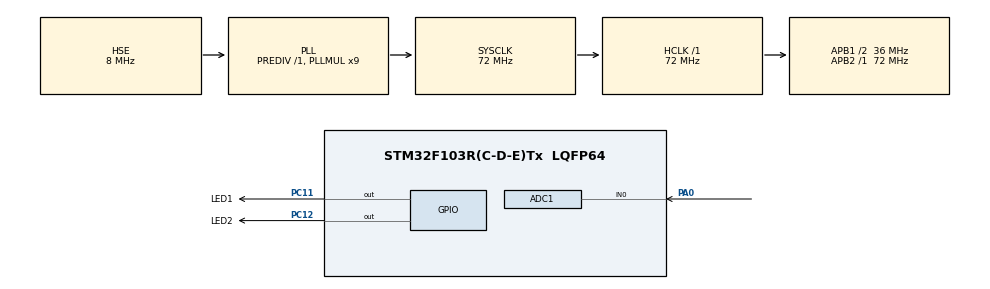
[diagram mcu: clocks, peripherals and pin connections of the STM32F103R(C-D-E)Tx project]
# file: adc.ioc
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ADC1.Channel-0\#ChannelRegularConversion=ADC_CHANNEL_0
ADC1.ContinuousConvMode=ENABLE
ADC1.DataAlign=ADC_DATAALIGN_RIGHT
ADC1.DiscontinuousConvMode=DISABLE
ADC1.EnableAnalogWatchDog=false
ADC1.EnableRegularConversion=ENABLE
ADC1.ExternalTrigConv=ADC_SOFTWARE_START
ADC1.InjNumberOfConversion=0
ADC1.NbrOfConversion=1
ADC1.NbrOfConversionFlag=1
ADC1.Rank-0\#ChannelRegularConversion=1
ADC1.SamplingTime-0\#ChannelRegularConversion=ADC_SAMPLETIME_1CYCLE_5
ADC1.ScanConvMode=ADC_SCAN_DISABLE
ADC1.master=1
Dma.ADC1.0.Direction=DMA_PERIPH_TO_MEMORY
Dma.ADC1.0.Instance=DMA1_Channel1
Dma.ADC1.0.MemDataAlignment=DMA_MDATAALIGN_HALFWORD
Dma.ADC1.0.MemInc=DMA_MINC_ENABLE
Dma.ADC1.0.Mode=DMA_CIRCULAR
Dma.ADC1.0.PeriphDataAlignment=DMA_PDATAALIGN_HALFWORD
Dma.ADC1.0.PeriphInc=DMA_PINC_DISABLE
Dma.ADC1.0.Priority=DMA_PRIORITY_LOW
Dma.Request0=ADC1
Mcu.Family=STM32F1
Mcu.Name=STM32F103R(C-D-E)Tx
Mcu.Package=LQFP64
NVIC.ADC1_2_IRQn=true\:1\:0\:true\:false\:true\:true
NVIC.DMA1_Channel1_IRQn=true\:0\:0\:false\:false\:true\:false
NVIC.PriorityGroup=NVIC_PRIORITYGROUP_4
PA0-WKUP.Signal=ADCx_IN0
PA13.Mode=Serial_Wire
PA13.Signal=SYS_JTMS-SWDIO
PA14.Mode=Serial_Wire
PA14.Signal=SYS_JTCK-SWCLK
PC11.GPIO_Label=LED1
PC11.Signal=GPIO_Output
PC12.GPIO_Label=LED2
PC12.Signal=GPIO_Output
PD0-OSC_IN.Mode=HSE-External-Oscillator
PD0-OSC_IN.Signal=RCC_OSC_IN
PD1-OSC_OUT.Mode=HSE-External-Oscillator
PD1-OSC_OUT.Signal=RCC_OSC_OUT
ProjectManager.HeapSize=0x200
ProjectManager.StackSize=0x400
ProjectManager.TargetToolchain=MDK-ARM V5
RCC.ADCPresc=RCC_ADCPCLK2_DIV6
RCC.AHBFreq_Value=72000000
RCC.APB1CLKDivider=RCC_HCLK_DIV2
RCC.APB1Freq_Value=36000000
RCC.APB1TimFreq_Value=72000000
RCC.APB2Freq_Value=72000000
RCC.APB2TimFreq_Value=72000000
RCC.HCLKFreq_Value=72000000
RCC.PLLMUL=RCC_PLL_MUL9
RCC.PLLSourceVirtual=RCC_PLLSOURCE_HSE
RCC.SYSCLKFreq_VALUE=72000000
RCC.SYSCLKSource=RCC_SYSCLKSOURCE_PLLCLK
RCC.USBFreq_Value=72000000
SH.ADCx_IN0.0=ADC1_IN0,IN0
board=adc

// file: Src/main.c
/**
  ******************************************************************************
  * File Name          : main.c
  * Description        : Main program body
  ******************************************************************************
  ** This notice applies to any and all portions of this file
  * that are not between comment pairs USER CODE BEGIN and
  * USER CODE END. Other portions of this file, whether
  * inserted by the user or by software development tools
  * are owned by their respective copyright owners.
  *
  * COPYRIGHT(c) 2020 STMicroelectronics
  *
  * Redistribution and use in source and binary forms, with or without modification,
  * are permitted provided that the following conditions are met:
  *   1. Redistributions of source code must retain the above copyright notice,
  *      this list of conditions and the following disclaimer.
  *   2. Redistributions in binary form must reproduce the above copyright notice,
  *      this list of conditions and the following disclaimer in the documentation
  *      and/or other materials provided with the distribution.
  *   3. Neither the name of STMicroelectronics nor the names of its contributors
  *      may be used to endorse or promote products derived from this software
  *      without specific prior written permission.
  *
  * THIS SOFTWARE IS PROVIDED BY THE COPYRIGHT HOLDERS AND CONTRIBUTORS "AS IS"
  * AND ANY EXPRESS OR IMPLIED WARRANTIES, INCLUDING, BUT NOT LIMITED TO, THE
  * IMPLIED WARRANTIES OF MERCHANTABILITY AND FITNESS FOR A PARTICULAR PURPOSE ARE
  * DISCLAIMED. IN NO EVENT SHALL THE COPYRIGHT HOLDER OR CONTRIBUTORS BE LIABLE
  * FOR ANY DIRECT, INDIRECT, INCIDENTAL, SPECIAL, EXEMPLARY, OR CONSEQUENTIAL
  * DAMAGES (INCLUDING, BUT NOT LIMITED TO, PROCUREMENT OF SUBSTITUTE GOODS OR
  * SERVICES; LOSS OF USE, DATA, OR PROFITS; OR BUSINESS INTERRUPTION) HOWEVER
  * CAUSED AND ON ANY THEORY OF LIABILITY, WHETHER IN CONTRACT, STRICT LIABILITY,
  * OR TORT (INCLUDING NEGLIGENCE OR OTHERWISE) ARISING IN ANY WAY OUT OF THE USE
  * OF THIS SOFTWARE, EVEN IF ADVISED OF THE POSSIBILITY OF SUCH DAMAGE.
  *
  ******************************************************************************
  */

#include "main.h"
#include "stm32f1xx_hal.h"

ADC_HandleTypeDef hadc1;
DMA_HandleTypeDef hdma_adc1;

/* USER CODE BEGIN PV */
/* Private variables ---------------------------------------------------------*/
volatile uint32_t adc ;
/* USER CODE END PV */

void SystemClock_Config(void);
static void MX_GPIO_Init(void);
static void MX_DMA_Init(void);
static void MX_ADC1_Init(void);

/* USER CODE BEGIN PFP */
/* Private function prototypes -----------------------------------------------*/

/* USER CODE END PFP */

/* USER CODE BEGIN 0 */
void HAL_ADC_ConvCpltCallback(ADC_HandleTypeDef* hadc)
{
	//HAL_ADC_Start(&hadc1);
	if(hadc->Instance==hadc1.Instance){
		if(HAL_ADC_GetValue(&hadc1) > 3000){
			HAL_GPIO_WritePin(LED2_GPIO_Port, LED2_Pin,GPIO_PIN_SET);
			HAL_GPIO_WritePin(LED1_GPIO_Port,LED1_Pin,GPIO_PIN_RESET);
			adc = HAL_ADC_GetValue(&hadc1);
		}
		else {
			HAL_GPIO_WritePin(LED2_GPIO_Port,LED2_Pin,0);
			adc= 0;
			HAL_ADC_Stop_IT(&hadc1);

		}
	}
}

/* USER CODE END 0 */

int main(void)
{

  /* MCU Configuration----------------------------------------------------------*/

  /* Reset of all peripherals, Initializes the Flash interface and the Systick. */
  HAL_Init();

  /* Configure the system clock */
  SystemClock_Config();

  /* Initialize all configured peripherals */
  MX_GPIO_Init();
  MX_DMA_Init();
  MX_ADC1_Init();
	HAL_ADC_Start_IT(&hadc1);
	//HAL_ADC_Start(&hadc1);

  /* Infinite loop */
  while (1)
  {
		HAL_GPIO_TogglePin(LED1_GPIO_Port,LED1_Pin);
		HAL_Delay(1000);
		HAL_GPIO_TogglePin(LED2_GPIO_Port,LED2_Pin);
		HAL_Delay(1100);
		HAL_ADC_Start_IT(&hadc1);
  }

}

/** System Clock Configuration
*/

void SystemClock_Config(void)
{

  RCC_OscInitTypeDef RCC_OscInitStruct;
  RCC_ClkInitTypeDef RCC_ClkInitStruct;
  RCC_PeriphCLKInitTypeDef PeriphClkInit;

    /**Initializes the CPU, AHB and APB busses clocks
    */
  RCC_OscInitStruct.OscillatorType = RCC_OSCILLATORTYPE_HSE;
  RCC_OscInitStruct.HSEState = RCC_HSE_ON;
  RCC_OscInitStruct.HSEPredivValue = RCC_HSE_PREDIV_DIV1;
  RCC_OscInitStruct.HSIState = RCC_HSI_ON;
  RCC_OscInitStruct.PLL.PLLState = RCC_PLL_ON;
  RCC_OscInitStruct.PLL.PLLSource = RCC_PLLSOURCE_HSE;
  RCC_OscInitStruct.PLL.PLLMUL = RCC_PLL_MUL9;
  if (HAL_RCC_OscConfig(&RCC_OscInitStruct) != HAL_OK)
  {
    _Error_Handler(__FILE__, __LINE__);
  }

    /**Initializes the CPU, AHB and APB busses clocks
    */
  RCC_ClkInitStruct.ClockType = RCC_CLOCKTYPE_HCLK|RCC_CLOCKTYPE_SYSCLK
                              |RCC_CLOCKTYPE_PCLK1|RCC_CLOCKTYPE_PCLK2;
  RCC_ClkInitStruct.SYSCLKSource = RCC_SYSCLKSOURCE_PLLCLK;
  RCC_ClkInitStruct.AHBCLKDivider = RCC_SYSCLK_DIV1;
  RCC_ClkInitStruct.APB1CLKDivider = RCC_HCLK_DIV2;
  RCC_ClkInitStruct.APB2CLKDivider = RCC_HCLK_DIV1;

  if (HAL_RCC_ClockConfig(&RCC_ClkInitStruct, FLASH_LATENCY_2) != HAL_OK)
  {
    _Error_Handler(__FILE__, __LINE__);
  }

  PeriphClkInit.PeriphClockSelection = RCC_PERIPHCLK_ADC;
  PeriphClkInit.AdcClockSelection = RCC_ADCPCLK2_DIV6;
  if (HAL_RCCEx_PeriphCLKConfig(&PeriphClkInit) != HAL_OK)
  {
    _Error_Handler(__FILE__, __LINE__);
  }

    /**Configure the Systick interrupt time
    */
  HAL_SYSTICK_Config(HAL_RCC_GetHCLKFreq()/1000);

    /**Configure the Systick
    */
  HAL_SYSTICK_CLKSourceConfig(SYSTICK_CLKSOURCE_HCLK);

  /* SysTick_IRQn interrupt configuration */
  HAL_NVIC_SetPriority(SysTick_IRQn, 0, 0);
}

/* ADC1 init function */
static void MX_ADC1_Init(void)
{

  ADC_ChannelConfTypeDef sConfig;

    /**Common config
    */
  hadc1.Instance = ADC1;
  hadc1.Init.ScanConvMode = ADC_SCAN_DISABLE;
  hadc1.Init.ContinuousConvMode = ENABLE;
  hadc1.Init.DiscontinuousConvMode = DISABLE;
  hadc1.Init.ExternalTrigConv = ADC_SOFTWARE_START;
  hadc1.Init.DataAlign = ADC_DATAALIGN_RIGHT;
  hadc1.Init.NbrOfConversion = 1;
  if (HAL_ADC_Init(&hadc1) != HAL_OK)
  {
    _Error_Handler(__FILE__, __LINE__);
  }

    /**Configure Regular Channel
    */
  sConfig.Channel = ADC_CHANNEL_0;
  sConfig.Rank = 1;
  sConfig.SamplingTime = ADC_SAMPLETIME_1CYCLE_5;
  if (HAL_ADC_ConfigChannel(&hadc1, &sConfig) != HAL_OK)
  {
    _Error_Handler(__FILE__, __LINE__);
  }

}

static void MX_DMA_Init(void)
{
  /* DMA controller clock enable */
  __HAL_RCC_DMA1_CLK_ENABLE();

  /* DMA interrupt init */
  /* DMA1_Channel1_IRQn interrupt configuration */
  HAL_NVIC_SetPriority(DMA1_Channel1_IRQn, 0, 0);
  HAL_NVIC_EnableIRQ(DMA1_Channel1_IRQn);

}

/** Configure pins as
        * Analog
        * Input
        * Output
        * EVENT_OUT
        * EXTI
*/
static void MX_GPIO_Init(void)
{

  GPIO_InitTypeDef GPIO_InitStruct;

  /* GPIO Ports Clock Enable */
  __HAL_RCC_GPIOD_CLK_ENABLE();
  __HAL_RCC_GPIOA_CLK_ENABLE();
  __HAL_RCC_GPIOC_CLK_ENABLE();

  /*Configure GPIO pin Output Level */
  HAL_GPIO_WritePin(GPIOC, LED1_Pin|LED2_Pin, GPIO_PIN_RESET);

  /*Configure GPIO pins : LED1_Pin LED2_Pin */
  GPIO_InitStruct.Pin = LED1_Pin|LED2_Pin;
  GPIO_InitStruct.Mode = GPIO_MODE_OUTPUT_PP;
  GPIO_InitStruct.Speed = GPIO_SPEED_FREQ_LOW;
  HAL_GPIO_Init(GPIOC, &GPIO_InitStruct);

}

void _Error_Handler(char * file, int line)
{
  while(1)
  {
  }
}

/************************ (C) COPYRIGHT STMicroelectronics *****END OF FILE****/
